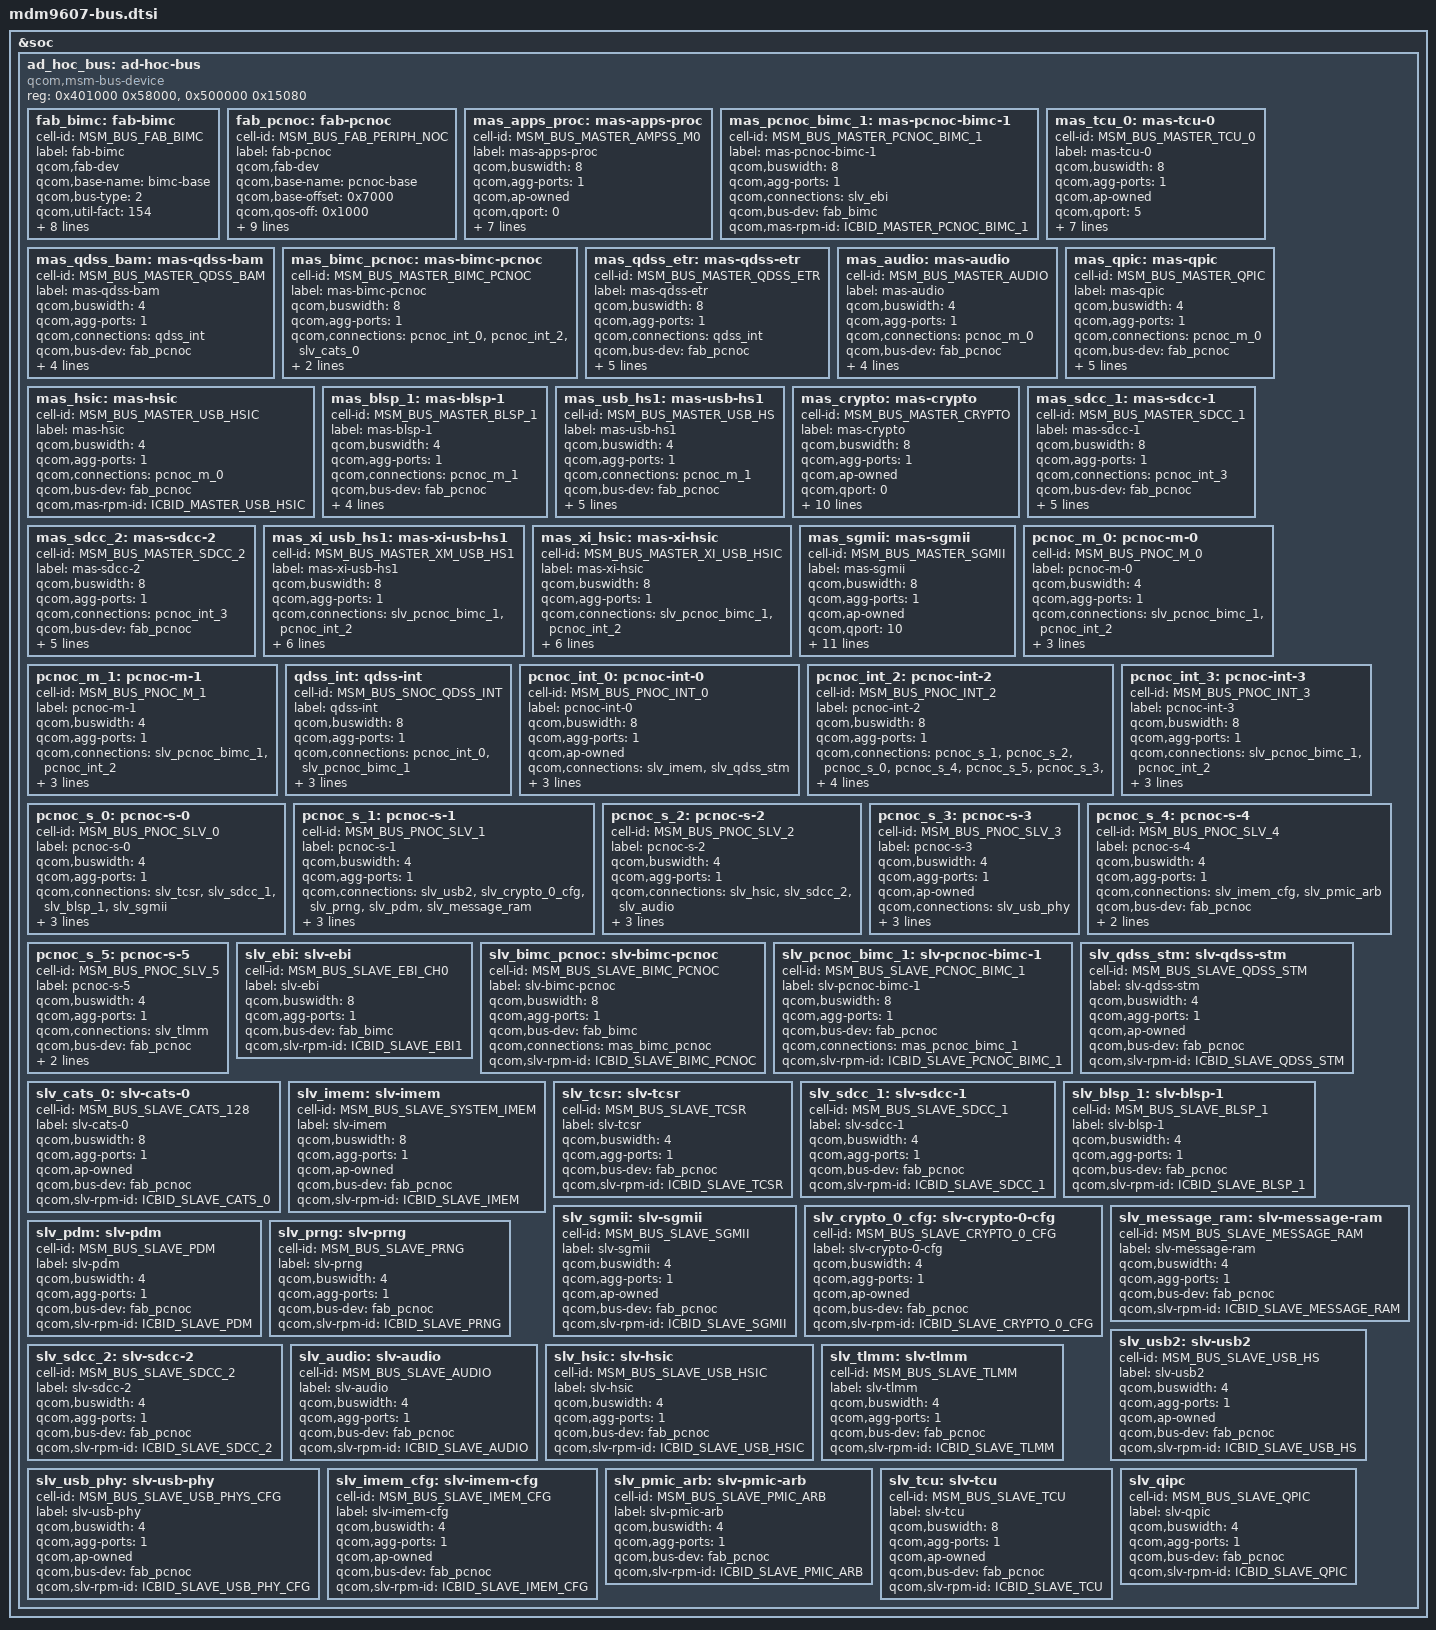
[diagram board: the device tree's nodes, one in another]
/* Copyright (c) 2019, The Linux Foundation. All rights reserved.
 *
 * This program is free software; you can redistribute it and/or modify
 * it under the terms of the GNU General Public License version 2 and
 * only version 2 as published by the Free Software Foundation.
 *
 * This program is distributed in the hope that it will be useful,
 * but WITHOUT ANY WARRANTY; without even the implied warranty of
 * MERCHANTABILITY or FITNESS FOR A PARTICULAR PURPOSE.  See the
 * GNU General Public License for more details.
 */

#include <dt-bindings/msm/msm-bus-ids.h>

&soc {
	/* Version = 1 */
	ad_hoc_bus: ad-hoc-bus {
		compatible = "qcom,msm-bus-device";
		reg = <0x401000 0x58000>,
		      <0x500000 0x15080>;
		reg-names = "bimc-base", "pcnoc-base";

		/*Buses*/

		fab_bimc: fab-bimc {
			cell-id = <MSM_BUS_FAB_BIMC>;
			label = "fab-bimc";
			qcom,fab-dev;
			qcom,base-name = "bimc-base";
			qcom,bus-type = <2>;
			qcom,util-fact = <154>;
			clock-names = "bus_clk", "bus_a_clk";
			clocks = <&clock_gcc  clk_bimc_msmbus_clk>,
				<&clock_gcc  clk_bimc_msmbus_a_clk>;

			coresight-id = <203>;
			coresight-name = "coresight-bimc";
			coresight-nr-inports = <0>;
			coresight-outports = <0>;
			coresight-child-list = <&funnel_in0>;
			coresight-child-ports = <3>;
		};

		fab_pcnoc: fab-pcnoc {
			cell-id = <MSM_BUS_FAB_PERIPH_NOC>;
			label = "fab-pcnoc";
			qcom,fab-dev;
			qcom,base-name = "pcnoc-base";
			qcom,base-offset = <0x7000>;
			qcom,qos-off = <0x1000>;
			qcom,bus-type = <1>;
			clock-names = "bus_clk", "bus_a_clk";
			clocks = <&clock_gcc  clk_pcnoc_msmbus_clk>,
				<&clock_gcc  clk_pcnoc_msmbus_a_clk>;

			coresight-id = <201>;
			coresight-name = "coresight-pcnoc";
			coresight-nr-inports = <0>;
			coresight-outports = <0>;
			coresight-child-list = <&funnel_in2>;
			coresight-child-ports = <0>;
		};

		/*Masters*/

		mas_apps_proc: mas-apps-proc {
			cell-id = <MSM_BUS_MASTER_AMPSS_M0>;
			label = "mas-apps-proc";
			qcom,buswidth = <8>;
			qcom,agg-ports = <1>;
			qcom,ap-owned;
			qcom,qport = <0>;
			qcom,qos-mode = "fixed";
			qcom,connections = < &slv_bimc_pcnoc &slv_ebi>;
			qcom,prio-lvl = <0>;
			qcom,prio-rd = <0>;
			qcom,prio-wr = <0>;
			qcom,bus-dev = <&fab_bimc>;
			qcom,mas-rpm-id = <ICBID_MASTER_APPSS_PROC>;
		};

		mas_pcnoc_bimc_1: mas-pcnoc-bimc-1 {
			cell-id = <MSM_BUS_MASTER_PCNOC_BIMC_1>;
			label = "mas-pcnoc-bimc-1";
			qcom,buswidth = <8>;
			qcom,agg-ports = <1>;
			qcom,connections = <&slv_ebi>;
			qcom,bus-dev = <&fab_bimc>;
			qcom,mas-rpm-id = <ICBID_MASTER_PCNOC_BIMC_1>;
		};

		mas_tcu_0: mas-tcu-0 {
			cell-id = <MSM_BUS_MASTER_TCU_0>;
			label = "mas-tcu-0";
			qcom,buswidth = <8>;
			qcom,agg-ports = <1>;
			qcom,ap-owned;
			qcom,qport = <5>;
			qcom,qos-mode = "fixed";
			qcom,connections = <&slv_ebi>;
			qcom,prio-lvl = <2>;
			qcom,prio-rd = <2>;
			qcom,prio-wr = <2>;
			qcom,bus-dev = <&fab_bimc>;
			qcom,mas-rpm-id = <ICBID_MASTER_TCU_0>;
		};

		mas_qdss_bam: mas-qdss-bam {
			cell-id = <MSM_BUS_MASTER_QDSS_BAM>;
			label = "mas-qdss-bam";
			qcom,buswidth = <4>;
			qcom,agg-ports = <1>;
			qcom,connections = <&qdss_int>;
			qcom,bus-dev = <&fab_pcnoc>;
			qcom,mas-rpm-id = <ICBID_MASTER_QDSS_BAM>;
			qcom,blacklist = <&pcnoc_s_1 &pcnoc_s_2 &pcnoc_s_0
				 &pcnoc_s_4 &pcnoc_s_5 &pcnoc_s_3 &slv_tcu>;
		};

		mas_bimc_pcnoc: mas-bimc-pcnoc {
			cell-id = <MSM_BUS_MASTER_BIMC_PCNOC>;
			label = "mas-bimc-pcnoc";
			qcom,buswidth = <8>;
			qcom,agg-ports = <1>;
			qcom,connections = <&pcnoc_int_0
				 &pcnoc_int_2 &slv_cats_0>;
			qcom,bus-dev = <&fab_pcnoc>;
			qcom,mas-rpm-id = <ICBID_MASTER_BIMC_PCNOC>;
		};

		mas_qdss_etr: mas-qdss-etr {
			cell-id = <MSM_BUS_MASTER_QDSS_ETR>;
			label = "mas-qdss-etr";
			qcom,buswidth = <8>;
			qcom,agg-ports = <1>;
			qcom,connections = <&qdss_int>;
			qcom,bus-dev = <&fab_pcnoc>;
			qcom,mas-rpm-id = <ICBID_MASTER_QDSS_ETR>;
			qcom,blacklist = <&pcnoc_s_0 &pcnoc_s_2
					  &pcnoc_s_3 &pcnoc_s_4 &pcnoc_s_5
					  &slv_crypto_0_cfg &slv_message_ram
					  &slv_pdm &slv_prng &slv_qdss_stm
					  &slv_tcu>;
		};

		mas_audio: mas-audio {
			cell-id = <MSM_BUS_MASTER_AUDIO>;
			label = "mas-audio";
			qcom,buswidth = <4>;
			qcom,agg-ports = <1>;
			qcom,connections = <&pcnoc_m_0>;
			qcom,bus-dev = <&fab_pcnoc>;
			qcom,mas-rpm-id = <ICBID_MASTER_AUDIO>;
			qcom,blacklist = <&pcnoc_s_0 &pcnoc_s_1
					 &pcnoc_s_2 &pcnoc_s_3
					 &pcnoc_s_4 &pcnoc_s_5 &slv_tcu>;
		};

		mas_qpic: mas-qpic {
			cell-id = <MSM_BUS_MASTER_QPIC>;
			label = "mas-qpic";
			qcom,buswidth = <4>;
			qcom,agg-ports = <1>;
			qcom,connections = <&pcnoc_m_0>;
			qcom,bus-dev = <&fab_pcnoc>;
			qcom,mas-rpm-id = <ICBID_MASTER_QPIC>;
			qcom,blacklist = <&pcnoc_s_0 &pcnoc_s_2
					  &pcnoc_s_3 &pcnoc_s_4
					  &pcnoc_s_5 &slv_tcu
					  &slv_crypto_0_cfg &slv_pdm
					  &slv_prng &slv_usb2 >;
		};

		mas_hsic: mas-hsic {
			cell-id = <MSM_BUS_MASTER_USB_HSIC>;
			label = "mas-hsic";
			qcom,buswidth = <4>;
			qcom,agg-ports = <1>;
			qcom,connections = <&pcnoc_m_0>;
			qcom,bus-dev = <&fab_pcnoc>;
			qcom,mas-rpm-id = <ICBID_MASTER_USB_HSIC>;
		};

		mas_blsp_1: mas-blsp-1 {
			cell-id = <MSM_BUS_MASTER_BLSP_1>;
			label = "mas-blsp-1";
			qcom,buswidth = <4>;
			qcom,agg-ports = <1>;
			qcom,connections = <&pcnoc_m_1>;
			qcom,bus-dev = <&fab_pcnoc>;
			qcom,mas-rpm-id = <ICBID_MASTER_BLSP_1>;
			qcom,blacklist = <&pcnoc_s_0 &pcnoc_s_1
					 &pcnoc_s_2 &pcnoc_s_3
					 &pcnoc_s_4 &pcnoc_s_5 &slv_tcu >;
		};

		mas_usb_hs1: mas-usb-hs1 {
			cell-id = <MSM_BUS_MASTER_USB_HS>;
			label = "mas-usb-hs1";
			qcom,buswidth = <4>;
			qcom,agg-ports = <1>;
			qcom,connections = <&pcnoc_m_1>;
			qcom,bus-dev = <&fab_pcnoc>;
			qcom,mas-rpm-id = <ICBID_MASTER_USB_HS1>;
			qcom,blacklist = <&pcnoc_s_0 &pcnoc_s_2 &pcnoc_s_4
					 &pcnoc_s_5 &slv_tcu
					 &slv_crypto_0_cfg
					 &slv_pdm &slv_prng &slv_usb2
					 &slv_usb_phy> ;
		};

		mas_crypto: mas-crypto {
			cell-id = <MSM_BUS_MASTER_CRYPTO>;
			label = "mas-crypto";
			qcom,buswidth = <8>;
			qcom,agg-ports = <1>;
			qcom,ap-owned;
			qcom,qport = <0>;
			qcom,qos-mode = "fixed";
			qcom,connections = <&pcnoc_int_3>;
			qcom,prio1 = <2>;
			qcom,prio0 = <2>;
			qcom,bus-dev = <&fab_pcnoc>;
			qcom,mas-rpm-id = <ICBID_MASTER_CRYPTO>;
			qcom,blacklist = <&pcnoc_s_0 &pcnoc_s_2 &pcnoc_s_3
					  &pcnoc_s_4 &pcnoc_s_5 &slv_tcu
					  &slv_crypto_0_cfg &slv_pdm
					  &slv_usb2 &slv_prng>;
		};

		mas_sdcc_1: mas-sdcc-1 {
			cell-id = <MSM_BUS_MASTER_SDCC_1>;
			label = "mas-sdcc-1";
			qcom,buswidth = <8>;
			qcom,agg-ports = <1>;
			qcom,connections = <&pcnoc_int_3>;
			qcom,bus-dev = <&fab_pcnoc>;
			qcom,mas-rpm-id = <ICBID_MASTER_SDCC_1>;
			qcom,blacklist = <&pcnoc_s_0 &pcnoc_s_2 &pcnoc_s_3
					 &pcnoc_s_4 &pcnoc_s_5 &slv_tcu
					 &slv_crypto_0_cfg &slv_pdm
					 &slv_usb2 &slv_prng>;
		};

		mas_sdcc_2: mas-sdcc-2 {
			cell-id = <MSM_BUS_MASTER_SDCC_2>;
			label = "mas-sdcc-2";
			qcom,buswidth = <8>;
			qcom,agg-ports = <1>;
			qcom,connections = <&pcnoc_int_3>;
			qcom,bus-dev = <&fab_pcnoc>;
			qcom,mas-rpm-id = <ICBID_MASTER_SDCC_2>;
			qcom,blacklist = <&pcnoc_s_0 &pcnoc_s_2 &pcnoc_s_3
					 &pcnoc_s_4 &pcnoc_s_5 &slv_tcu
					 &slv_crypto_0_cfg &slv_pdm
					 &slv_usb2 &slv_prng>;
		};

		mas_xi_usb_hs1: mas-xi-usb-hs1 {
			cell-id = <MSM_BUS_MASTER_XM_USB_HS1>;
			label = "mas-xi-usb-hs1";
			qcom,buswidth = <8>;
			qcom,agg-ports = <1>;
			qcom,connections = <&slv_pcnoc_bimc_1 &pcnoc_int_2>;
			qcom,bus-dev = <&fab_pcnoc>;
			qcom,mas-rpm-id = <ICBID_MASTER_XI_USB_HS1>;
			qcom,blacklist = <&pcnoc_s_0 &pcnoc_s_2 &pcnoc_s_4
					 &pcnoc_s_5 &slv_tcu &slv_crypto_0_cfg
					 &slv_pdm &slv_usb2 &slv_prng
					 &slv_usb_phy>;
		};

		mas_xi_hsic: mas-xi-hsic {
			cell-id = <MSM_BUS_MASTER_XI_USB_HSIC>;
			label = "mas-xi-hsic";
			qcom,buswidth = <8>;
			qcom,agg-ports = <1>;
			qcom,connections = <&slv_pcnoc_bimc_1 &pcnoc_int_2>;
			qcom,bus-dev = <&fab_pcnoc>;
			qcom,mas-rpm-id = <ICBID_MASTER_XI_HSIC>;
			qcom,blacklist = <&pcnoc_s_0 &pcnoc_s_2
					 &pcnoc_s_3 &pcnoc_s_4 &pcnoc_s_5
					 &slv_tcu &slv_crypto_0_cfg
					 &slv_pdm &slv_usb2 &slv_prng>;
		};

		mas_sgmii: mas-sgmii {
			cell-id = <MSM_BUS_MASTER_SGMII>;
			label = "mas-sgmii";
			qcom,buswidth = <8>;
			qcom,agg-ports = <1>;
			qcom,ap-owned;
			qcom,qport = <10>;
			qcom,qos-mode = "fixed";
			qcom,connections = <&slv_pcnoc_bimc_1 &pcnoc_int_2>;
			qcom,prio1 = <1>;
			qcom,prio0 = <1>;
			qcom,bus-dev = <&fab_pcnoc>;
			qcom,mas-rpm-id = <ICBID_MASTER_SGMII>;
			qcom,blacklist = <&pcnoc_s_0 &pcnoc_s_2 &pcnoc_s_3
					 &pcnoc_s_4 &pcnoc_s_5 &slv_tcu
					 &slv_crypto_0_cfg &slv_pdm
					 &slv_usb2 &slv_prng>;
		};

		/*Internal nodes*/

		pcnoc_m_0: pcnoc-m-0 {
			cell-id = <MSM_BUS_PNOC_M_0>;
			label = "pcnoc-m-0";
			qcom,buswidth = <4>;
			qcom,agg-ports = <1>;
			qcom,connections = <&slv_pcnoc_bimc_1 &pcnoc_int_2>;
			qcom,bus-dev = <&fab_pcnoc>;
			qcom,mas-rpm-id = <ICBID_MASTER_PCNOC_M_0>;
			qcom,slv-rpm-id = <ICBID_SLAVE_PCNOC_M_0>;
		};

		pcnoc_m_1: pcnoc-m-1 {
			cell-id = <MSM_BUS_PNOC_M_1>;
			label = "pcnoc-m-1";
			qcom,buswidth = <4>;
			qcom,agg-ports = <1>;
			qcom,connections = <&slv_pcnoc_bimc_1 &pcnoc_int_2>;
			qcom,bus-dev = <&fab_pcnoc>;
			qcom,mas-rpm-id = <ICBID_MASTER_PCNOC_M_1>;
			qcom,slv-rpm-id = <ICBID_SLAVE_PCNOC_M_1>;
		};

		qdss_int: qdss-int {
			cell-id = <MSM_BUS_SNOC_QDSS_INT>;
			label = "qdss-int";
			qcom,buswidth = <8>;
			qcom,agg-ports = <1>;
			qcom,connections = <&pcnoc_int_0 &slv_pcnoc_bimc_1>;
			qcom,bus-dev = <&fab_pcnoc>;
			qcom,mas-rpm-id = <ICBID_MASTER_QDSS_INT>;
			qcom,slv-rpm-id = <ICBID_SLAVE_QDSS_INT>;
		};

		pcnoc_int_0: pcnoc-int-0 {
			cell-id = <MSM_BUS_PNOC_INT_0>;
			label = "pcnoc-int-0";
			qcom,buswidth = <8>;
			qcom,agg-ports = <1>;
			qcom,ap-owned;
			qcom,connections = <&slv_imem &slv_qdss_stm>;
			qcom,bus-dev = <&fab_pcnoc>;
			qcom,mas-rpm-id = <ICBID_MASTER_PCNOC_INT_0>;
			qcom,slv-rpm-id = <ICBID_SLAVE_PCNOC_INT_0>;
		};

		pcnoc_int_2: pcnoc-int-2 {
			cell-id = <MSM_BUS_PNOC_INT_2>;
			label = "pcnoc-int-2";
			qcom,buswidth = <8>;
			qcom,agg-ports = <1>;
			qcom,connections = <&pcnoc_s_1 &pcnoc_s_2
					 &pcnoc_s_0 &pcnoc_s_4
					 &pcnoc_s_5 &pcnoc_s_3
					 &slv_tcu >;
			qcom,bus-dev = <&fab_pcnoc>;
			qcom,mas-rpm-id = <ICBID_MASTER_PCNOC_INT_2>;
			qcom,slv-rpm-id = <ICBID_SLAVE_PCNOC_INT_2>;
		};

		pcnoc_int_3: pcnoc-int-3 {
			cell-id = <MSM_BUS_PNOC_INT_3>;
			label = "pcnoc-int-3";
			qcom,buswidth = <8>;
			qcom,agg-ports = <1>;
			qcom,connections = <&slv_pcnoc_bimc_1 &pcnoc_int_2>;
			qcom,bus-dev = <&fab_pcnoc>;
			qcom,mas-rpm-id = <ICBID_MASTER_PCNOC_INT_3>;
			qcom,slv-rpm-id = <ICBID_SLAVE_PCNOC_INT_3>;
		};

		pcnoc_s_0: pcnoc-s-0 {
			cell-id = <MSM_BUS_PNOC_SLV_0>;
			label = "pcnoc-s-0";
			qcom,buswidth = <4>;
			qcom,agg-ports = <1>;
			qcom,connections = <&slv_tcsr &slv_sdcc_1 &slv_blsp_1
				 &slv_sgmii>;
			qcom,bus-dev = <&fab_pcnoc>;
			qcom,mas-rpm-id = <ICBID_MASTER_PCNOC_S_0>;
			qcom,slv-rpm-id = <ICBID_SLAVE_PCNOC_S_0>;
		};

		pcnoc_s_1: pcnoc-s-1 {
			cell-id = <MSM_BUS_PNOC_SLV_1>;
			label = "pcnoc-s-1";
			qcom,buswidth = <4>;
			qcom,agg-ports = <1>;
			qcom,connections = <&slv_usb2 &slv_crypto_0_cfg
					 &slv_prng &slv_pdm
					 &slv_message_ram>;
			qcom,bus-dev = <&fab_pcnoc>;
			qcom,mas-rpm-id = <ICBID_MASTER_PCNOC_S_1>;
			qcom,slv-rpm-id = <ICBID_SLAVE_PCNOC_S_1>;
		};

		pcnoc_s_2: pcnoc-s-2 {
			cell-id = <MSM_BUS_PNOC_SLV_2>;
			label = "pcnoc-s-2";
			qcom,buswidth = <4>;
			qcom,agg-ports = <1>;
			qcom,connections = <&slv_hsic &slv_sdcc_2 &slv_audio>;
			qcom,bus-dev = <&fab_pcnoc>;
			qcom,mas-rpm-id = <ICBID_MASTER_PCNOC_S_2>;
			qcom,slv-rpm-id = <ICBID_SLAVE_PCNOC_S_2>;
		};

		pcnoc_s_3: pcnoc-s-3 {
			cell-id = <MSM_BUS_PNOC_SLV_3>;
			label = "pcnoc-s-3";
			qcom,buswidth = <4>;
			qcom,agg-ports = <1>;
			qcom,ap-owned;
			qcom,connections = <&slv_usb_phy>;
			qcom,bus-dev = <&fab_pcnoc>;
			qcom,mas-rpm-id = <ICBID_MASTER_PCNOC_S_3>;
			qcom,slv-rpm-id = <ICBID_SLAVE_PCNOC_S_3>;
		};

		pcnoc_s_4: pcnoc-s-4 {
			cell-id = <MSM_BUS_PNOC_SLV_4>;
			label = "pcnoc-s-4";
			qcom,buswidth = <4>;
			qcom,agg-ports = <1>;
			qcom,connections = <&slv_imem_cfg &slv_pmic_arb>;
			qcom,bus-dev = <&fab_pcnoc>;
			qcom,mas-rpm-id = <ICBID_MASTER_PCNOC_S_4>;
			qcom,slv-rpm-id = <ICBID_SLAVE_PCNOC_S_4>;
		};

		pcnoc_s_5: pcnoc-s-5 {
			cell-id = <MSM_BUS_PNOC_SLV_5>;
			label = "pcnoc-s-5";
			qcom,buswidth = <4>;
			qcom,agg-ports = <1>;
			qcom,connections = <&slv_tlmm>;
			qcom,bus-dev = <&fab_pcnoc>;
			qcom,mas-rpm-id = <ICBID_MASTER_PCNOC_S_5>;
			qcom,slv-rpm-id = <ICBID_SLAVE_PCNOC_S_5>;
		};

		/*Slaves*/

		slv_ebi:slv-ebi {
			cell-id = <MSM_BUS_SLAVE_EBI_CH0>;
			label = "slv-ebi";
			qcom,buswidth = <8>;
			qcom,agg-ports = <1>;
			qcom,bus-dev = <&fab_bimc>;
			qcom,slv-rpm-id = <ICBID_SLAVE_EBI1>;
		};

		slv_bimc_pcnoc:slv-bimc-pcnoc {
			cell-id = <MSM_BUS_SLAVE_BIMC_PCNOC>;
			label = "slv-bimc-pcnoc";
			qcom,buswidth = <8>;
			qcom,agg-ports = <1>;
			qcom,bus-dev = <&fab_bimc>;
			qcom,connections = <&mas_bimc_pcnoc>;
			qcom,slv-rpm-id = <ICBID_SLAVE_BIMC_PCNOC>;
		};

		slv_pcnoc_bimc_1:slv-pcnoc-bimc-1 {
			cell-id = <MSM_BUS_SLAVE_PCNOC_BIMC_1>;
			label = "slv-pcnoc-bimc-1";
			qcom,buswidth = <8>;
			qcom,agg-ports = <1>;
			qcom,bus-dev = <&fab_pcnoc>;
			qcom,connections = <&mas_pcnoc_bimc_1>;
			qcom,slv-rpm-id = <ICBID_SLAVE_PCNOC_BIMC_1>;
		};

		slv_qdss_stm:slv-qdss-stm {
			cell-id = <MSM_BUS_SLAVE_QDSS_STM>;
			label = "slv-qdss-stm";
			qcom,buswidth = <4>;
			qcom,agg-ports = <1>;
			qcom,ap-owned;
			qcom,bus-dev = <&fab_pcnoc>;
			qcom,slv-rpm-id = <ICBID_SLAVE_QDSS_STM>;
		};

		slv_cats_0:slv-cats-0 {
			cell-id = <MSM_BUS_SLAVE_CATS_128>;
			label = "slv-cats-0";
			qcom,buswidth = <8>;
			qcom,agg-ports = <1>;
			qcom,ap-owned;
			qcom,bus-dev = <&fab_pcnoc>;
			qcom,slv-rpm-id = <ICBID_SLAVE_CATS_0>;
		};

		slv_imem:slv-imem {
			cell-id = <MSM_BUS_SLAVE_SYSTEM_IMEM>;
			label = "slv-imem";
			qcom,buswidth = <8>;
			qcom,agg-ports = <1>;
			qcom,ap-owned;
			qcom,bus-dev = <&fab_pcnoc>;
			qcom,slv-rpm-id = <ICBID_SLAVE_IMEM>;
		};

		slv_tcsr:slv-tcsr {
			cell-id = <MSM_BUS_SLAVE_TCSR>;
			label = "slv-tcsr";
			qcom,buswidth = <4>;
			qcom,agg-ports = <1>;
			qcom,bus-dev = <&fab_pcnoc>;
			qcom,slv-rpm-id = <ICBID_SLAVE_TCSR>;
		};

		slv_sdcc_1:slv-sdcc-1 {
			cell-id = <MSM_BUS_SLAVE_SDCC_1>;
			label = "slv-sdcc-1";
			qcom,buswidth = <4>;
			qcom,agg-ports = <1>;
			qcom,bus-dev = <&fab_pcnoc>;
			qcom,slv-rpm-id = <ICBID_SLAVE_SDCC_1>;
		};

		slv_blsp_1:slv-blsp-1 {
			cell-id = <MSM_BUS_SLAVE_BLSP_1>;
			label = "slv-blsp-1";
			qcom,buswidth = <4>;
			qcom,agg-ports = <1>;
			qcom,bus-dev = <&fab_pcnoc>;
			qcom,slv-rpm-id = <ICBID_SLAVE_BLSP_1>;
		};

		slv_sgmii:slv-sgmii {
			cell-id = <MSM_BUS_SLAVE_SGMII>;
			label = "slv-sgmii";
			qcom,buswidth = <4>;
			qcom,agg-ports = <1>;
			qcom,ap-owned;
			qcom,bus-dev = <&fab_pcnoc>;
			qcom,slv-rpm-id = <ICBID_SLAVE_SGMII>;
		};

		slv_crypto_0_cfg:slv-crypto-0-cfg {
			cell-id = <MSM_BUS_SLAVE_CRYPTO_0_CFG>;
			label = "slv-crypto-0-cfg";
			qcom,buswidth = <4>;
			qcom,agg-ports = <1>;
			qcom,ap-owned;
			qcom,bus-dev = <&fab_pcnoc>;
			qcom,slv-rpm-id = <ICBID_SLAVE_CRYPTO_0_CFG>;
		};

		slv_message_ram:slv-message-ram {
			cell-id = <MSM_BUS_SLAVE_MESSAGE_RAM>;
			label = "slv-message-ram";
			qcom,buswidth = <4>;
			qcom,agg-ports = <1>;
			qcom,bus-dev = <&fab_pcnoc>;
			qcom,slv-rpm-id = <ICBID_SLAVE_MESSAGE_RAM>;
		};

		slv_pdm:slv-pdm {
			cell-id = <MSM_BUS_SLAVE_PDM>;
			label = "slv-pdm";
			qcom,buswidth = <4>;
			qcom,agg-ports = <1>;
			qcom,bus-dev = <&fab_pcnoc>;
			qcom,slv-rpm-id = <ICBID_SLAVE_PDM>;
		};

		slv_prng:slv-prng {
			cell-id = <MSM_BUS_SLAVE_PRNG>;
			label = "slv-prng";
			qcom,buswidth = <4>;
			qcom,agg-ports = <1>;
			qcom,bus-dev = <&fab_pcnoc>;
			qcom,slv-rpm-id = <ICBID_SLAVE_PRNG>;
		};

		slv_usb2:slv-usb2 {
			cell-id = <MSM_BUS_SLAVE_USB_HS>;
			label = "slv-usb2";
			qcom,buswidth = <4>;
			qcom,agg-ports = <1>;
			qcom,ap-owned;
			qcom,bus-dev = <&fab_pcnoc>;
			qcom,slv-rpm-id = <ICBID_SLAVE_USB_HS>;
		};

		slv_sdcc_2:slv-sdcc-2 {
			cell-id = <MSM_BUS_SLAVE_SDCC_2>;
			label = "slv-sdcc-2";
			qcom,buswidth = <4>;
			qcom,agg-ports = <1>;
			qcom,bus-dev = <&fab_pcnoc>;
			qcom,slv-rpm-id = <ICBID_SLAVE_SDCC_2>;
		};

		slv_audio:slv-audio {
			cell-id = <MSM_BUS_SLAVE_AUDIO>;
			label = "slv-audio";
			qcom,buswidth = <4>;
			qcom,agg-ports = <1>;
			qcom,bus-dev = <&fab_pcnoc>;
			qcom,slv-rpm-id = <ICBID_SLAVE_AUDIO>;
		};

		slv_hsic:slv-hsic {
			cell-id = <MSM_BUS_SLAVE_USB_HSIC>;
			label = "slv-hsic";
			qcom,buswidth = <4>;
			qcom,agg-ports = <1>;
			qcom,bus-dev = <&fab_pcnoc>;
			qcom,slv-rpm-id = <ICBID_SLAVE_USB_HSIC>;
		};

		slv_usb_phy:slv-usb-phy {
			cell-id = <MSM_BUS_SLAVE_USB_PHYS_CFG>;
			label = "slv-usb-phy";
			qcom,buswidth = <4>;
			qcom,agg-ports = <1>;
			qcom,ap-owned;
			qcom,bus-dev = <&fab_pcnoc>;
			qcom,slv-rpm-id = <ICBID_SLAVE_USB_PHY_CFG>;
		};

		slv_tlmm:slv-tlmm {
			cell-id = <MSM_BUS_SLAVE_TLMM>;
			label = "slv-tlmm";
			qcom,buswidth = <4>;
			qcom,agg-ports = <1>;
			qcom,bus-dev = <&fab_pcnoc>;
			qcom,slv-rpm-id = <ICBID_SLAVE_TLMM>;
		};

		slv_imem_cfg:slv-imem-cfg {
			cell-id = <MSM_BUS_SLAVE_IMEM_CFG>;
			label = "slv-imem-cfg";
			qcom,buswidth = <4>;
			qcom,agg-ports = <1>;
			qcom,ap-owned;
			qcom,bus-dev = <&fab_pcnoc>;
			qcom,slv-rpm-id = <ICBID_SLAVE_IMEM_CFG>;
		};

		slv_pmic_arb:slv-pmic-arb {
			cell-id = <MSM_BUS_SLAVE_PMIC_ARB>;
			label = "slv-pmic-arb";
			qcom,buswidth = <4>;
			qcom,agg-ports = <1>;
			qcom,bus-dev = <&fab_pcnoc>;
			qcom,slv-rpm-id = <ICBID_SLAVE_PMIC_ARB>;
		};

		slv_tcu:slv-tcu {
			cell-id = <MSM_BUS_SLAVE_TCU>;
			label = "slv-tcu";
			qcom,buswidth = <8>;
			qcom,agg-ports = <1>;
			qcom,ap-owned;
			qcom,bus-dev = <&fab_pcnoc>;
			qcom,slv-rpm-id = <ICBID_SLAVE_TCU>;
		};

		slv_qipc {
			cell-id = <MSM_BUS_SLAVE_QPIC>;
			label = "slv-qpic";
			qcom,buswidth = <4>;
			qcom,agg-ports = <1>;
			qcom,bus-dev = <&fab_pcnoc>;
			qcom,slv-rpm-id = <ICBID_SLAVE_QPIC>;

		};
	};
};
